VERSION ""

NS_ :

BS_:

BU_:

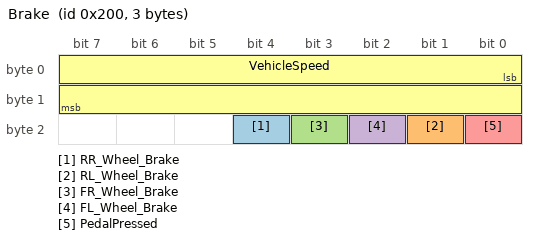
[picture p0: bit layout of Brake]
BO_ 512 Brake: 3 Vector__XXX
 SG_ RR_Wheel_Brake : 20|1@1+ (1,0) [0|0] "" Vector__XXX
 SG_ RL_Wheel_Brake : 17|1@1+ (1,0) [0|0] "" Vector__XXX
 SG_ FR_Wheel_Brake : 19|1@1+ (1,0) [0|0] "" Vector__XXX
 SG_ FL_Wheel_Brake : 18|1@1+ (1,0) [0|0] "" Vector__XXX
 SG_ PedalPressed : 16|1@1+ (1,0) [0|0] "" Vector__XXX
 SG_ VehicleSpeed : 0|16@1- (0.1,0) [0|0] "kph" Vector__XXX

BO_ 256 Engine: 6 Vector__XXX
 SG_ Torque : 32|16@1- (0.25,0) [0|0] "Nm" Vector__XXX
 SG_ RPM : 0|32@1- (1E-005,0) [0|0] "rpm" Vector__XXX

BA_DEF_  "BusType" STRING ;
BA_DEF_DEF_  "BusType" "CAN";
